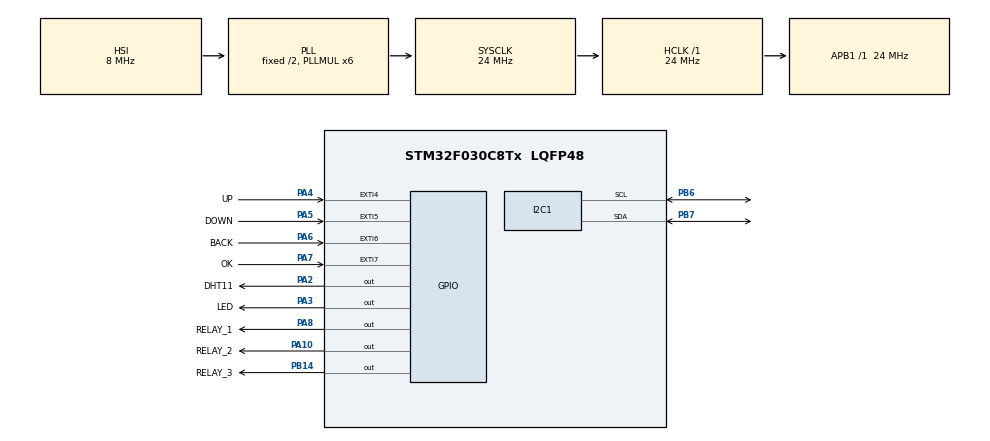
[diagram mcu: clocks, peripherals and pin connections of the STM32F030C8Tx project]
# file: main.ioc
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I2C1.Timing=0x00201D2B
Mcu.Family=STM32F0
Mcu.Name=STM32F030C8Tx
Mcu.Package=LQFP48
NVIC.EXTI4_15_IRQn=true\:0\:0\:false\:false\:true\:true\:true\:true
PA10.GPIO_Label=RELAY_2
PA10.GPIO_Speed=GPIO_SPEED_FREQ_HIGH
PA10.PinState=GPIO_PIN_SET
PA10.Signal=GPIO_Output
PA13.Mode=Serial_Wire
PA13.Signal=SYS_SWDIO
PA14.Mode=Serial_Wire
PA14.Signal=SYS_SWCLK
PA2.GPIO_Label=DHT11
PA2.Signal=GPIO_Output
PA3.GPIO_Label=LED
PA3.Signal=GPIO_Output
PA4.GPIO_Label=UP
PA4.Signal=GPXTI4
PA5.GPIO_Label=DOWN
PA5.Signal=GPXTI5
PA6.GPIO_Label=BACK
PA6.Signal=GPXTI6
PA7.GPIO_Label=OK
PA7.GPIO_ModeDefaultEXTI=GPIO_MODE_IT_RISING
PA7.Signal=GPXTI7
PA8.GPIO_Label=RELAY_1
PA8.GPIO_Speed=GPIO_SPEED_FREQ_HIGH
PA8.PinState=GPIO_PIN_SET
PA8.Signal=GPIO_Output
PB14.GPIO_Label=RELAY_3
PB14.GPIO_Speed=GPIO_SPEED_FREQ_HIGH
PB14.PinState=GPIO_PIN_SET
PB14.Signal=GPIO_Output
PB6.Mode=I2C
PB6.Signal=I2C1_SCL
PB7.Mode=I2C
PB7.Signal=I2C1_SDA
ProjectManager.HeapSize=0x200
ProjectManager.StackSize=0x400
ProjectManager.TargetToolchain=MDK-ARM V5.32
RCC.AHBFreq_Value=24000000
RCC.APB1Freq_Value=24000000
RCC.APB1TimFreq_Value=24000000
RCC.HCLKFreq_Value=24000000
RCC.PLLMUL=RCC_PLL_MUL6
RCC.SYSCLKFreq_VALUE=24000000
RCC.SYSCLKSource=RCC_SYSCLKSOURCE_PLLCLK
TIM3.Period=0xFFFF
TIM3.Prescaler=24-1
VP_TIM3_VS_ClockSourceINT.Mode=Internal
board=custom

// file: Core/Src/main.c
/* USER CODE BEGIN Header */
/**
  ******************************************************************************
  * @file           : main.c
  * @brief          : Main program body
  ******************************************************************************
  * @attention
  *
  * Copyright (c) 2025 STMicroelectronics.
  * All rights reserved.
  *
  * This software is licensed under terms that can be found in the LICENSE file
  * in the root directory of this software component.
  * If no LICENSE file comes with this software, it is provided AS-IS.
  *
  ******************************************************************************
  */
/* USER CODE END Header */
#include "main.h"

/* USER CODE BEGIN Includes */

#include "main.h"
#include "i2c-lcd.h"

#include "stdio.h"
#include "delay_timer.h"

/* USER CODE END Includes */

I2C_HandleTypeDef hi2c1;

TIM_HandleTypeDef htim3;

void SystemClock_Config(void);
static void MX_GPIO_Init(void);
static void MX_I2C1_Init(void);
static void MX_TIM3_Init(void);

/* USER CODE BEGIN 0 */

float a,b;
unsigned short int uiTimeLed = 0,uiTimeReadData = 0;
int TIME_READ_DATA = 100;

uint8_t Rh_byte1, Rh_byte2, Temp_byte1, Temp_byte2;
uint16_t SUM, RH, TEMP;

float Temperature = 0;
float Humidity = 0;
uint8_t Presence = 0;
float setTemp = 30, SET_OK = 30;

void Set_Pin_Output ()
{
	GPIO_InitTypeDef GPIO_InitStruct = {0};
	GPIO_InitStruct.Pin = DHT11_Pin;
	GPIO_InitStruct.Mode = GPIO_MODE_OUTPUT_PP;
	GPIO_InitStruct.Speed = GPIO_SPEED_FREQ_LOW;
	HAL_GPIO_Init(DHT11_GPIO_Port, &GPIO_InitStruct);
}

void Set_Pin_Input ()
{
	GPIO_InitTypeDef GPIO_InitStruct = {0};
	GPIO_InitStruct.Pin = DHT11_Pin;
	GPIO_InitStruct.Mode = GPIO_MODE_INPUT;
	GPIO_InitStruct.Pull = GPIO_PULLUP;
	HAL_GPIO_Init(DHT11_GPIO_Port, &GPIO_InitStruct);
}

void DHT11_Start (void){
		Set_Pin_Output();
		HAL_GPIO_WritePin(DHT11_GPIO_Port , DHT11_Pin ,GPIO_PIN_RESET);
		DELAY_TIM_Ms(&htim3, 20);
		HAL_GPIO_WritePin(DHT11_GPIO_Port , DHT11_Pin ,GPIO_PIN_SET);
		DELAY_TIM_Us(&htim3,40);
	  Set_Pin_Input();
}

uint8_t DHT11_Check_Response (void)
{
	uint8_t Response = 0;
	DELAY_TIM_Us(&htim3,40);
	if (!(HAL_GPIO_ReadPin (DHT11_GPIO_Port , DHT11_Pin)))
	{
		DELAY_TIM_Us(&htim3,80);
		if ((HAL_GPIO_ReadPin (DHT11_GPIO_Port , DHT11_Pin))) Response = 1;
		else Response = -1; // 255
	}
	while ((HAL_GPIO_ReadPin (DHT11_GPIO_Port , DHT11_Pin)));   // wait for the pin to go low

	return Response;
}

uint8_t DHT11_Read (void)
{
	uint8_t i,j;
	for (j=0;j<8;j++)
	{
		while (!(HAL_GPIO_ReadPin (DHT11_GPIO_Port , DHT11_Pin)));   // wait for the pin to go high
		DELAY_TIM_Us(&htim3,40);   // wait for 40 us
		if (!(HAL_GPIO_ReadPin (DHT11_GPIO_Port , DHT11_Pin)))   // if the pin is low
		{
			i&= ~(1<<(7-j));   // write 0
		}
		else i|= (1<<(7-j));  // if the pin is high, write 1
		while ((HAL_GPIO_ReadPin (DHT11_GPIO_Port , DHT11_Pin)));  // wait for the pin to go low
	}
	return i;
}

#define DEBOUNCE_DELAY      50
static uint32_t lastDebounceTime_UP   = 0;
static uint32_t lastDebounceTime_DOWN = 0;
static uint32_t lastDebounceTime_BACK = 0;
static uint32_t lastDebounceTime_OK   = 0;
 static uint8_t relayState = 0 ,relayState_1 = 0 ,relayState_2 = 0, relayState_3 = 0;
void HAL_GPIO_EXTI_Callback(uint16_t GPIO_Pin)
{
    uint32_t currentTick = HAL_GetTick();

    if (GPIO_Pin == UP_Pin)
    {
        if ((currentTick - lastDebounceTime_UP) >= DEBOUNCE_DELAY)
        {
            lastDebounceTime_UP = currentTick;
             relayState = !relayState;
            if (relayState)
            {
               setTemp +=1;
            }
        }
    }
    else if (GPIO_Pin == DOWN_Pin)
    {
        if ((currentTick - lastDebounceTime_DOWN) >= DEBOUNCE_DELAY)
        {
            lastDebounceTime_DOWN = currentTick;
         		relayState_1 = !relayState_1;
            if (relayState_1)
            {
                setTemp-=1;
            }
        }
    }
    else if (GPIO_Pin == BACK_Pin)
    {
        if ((currentTick - lastDebounceTime_BACK) >= DEBOUNCE_DELAY)
        {
            lastDebounceTime_BACK = currentTick;
					 relayState_3 = !relayState_3;
					 if (relayState_3)
            {
                HAL_GPIO_WritePin(GPIOA, RELAY_1_Pin|RELAY_2_Pin, GPIO_PIN_SET);
            }

						else{
							 HAL_GPIO_WritePin(GPIOA, RELAY_1_Pin|RELAY_2_Pin, GPIO_PIN_RESET);
						}
        }
    }
    else if (GPIO_Pin == OK_Pin)
    {
        if ((currentTick - lastDebounceTime_OK) >= DEBOUNCE_DELAY)
        {
            lastDebounceTime_OK = currentTick;
            relayState_2 = !relayState_2;
            if (relayState_2)
            {
                SET_OK = setTemp;
							 HAL_GPIO_WritePin(GPIOA, RELAY_1_Pin|RELAY_2_Pin, GPIO_PIN_SET);
            }
												else{
							 HAL_GPIO_WritePin(GPIOA, RELAY_1_Pin|RELAY_2_Pin, GPIO_PIN_RESET);
						}
        }
    }
}

void SysTick_Handler(void){
  HAL_IncTick();
	if(uiTimeLed != 0){
		uiTimeLed--;
	}
	if(uiTimeReadData != 0){
		uiTimeReadData--;
	}
}

char temp [100], hump[100];
int main(void)
{

  HAL_Init();
  SystemClock_Config();
  MX_GPIO_Init();
  MX_I2C1_Init();
  MX_TIM3_Init();
  /* USER CODE BEGIN 2 */
	DELAY_TIM_Init(&htim3);
	HAL_GPIO_WritePin(GPIOA, DHT11_Pin|LED_Pin, GPIO_PIN_SET);
	HAL_GPIO_WritePin(GPIOA, RELAY_1_Pin|RELAY_2_Pin, GPIO_PIN_RESET);
	lcd_init();
	sprintf(temp, "Nhiet do: %0.1f C", Temperature);
	sprintf(hump, "Do am: %0.1f%%", Humidity);
	lcd_put_cur(0, 0);
  lcd_send_string(temp);
  lcd_put_cur(1, 0);
  lcd_send_string(hump);
  /* USER CODE END 2 */

  /* Infinite loop */
  while (1)
  {
if(uiTimeLed == 0)
		{
			uiTimeLed = 1000;
		}
		else if(uiTimeLed <= 150)
		{
				HAL_GPIO_WritePin(GPIOA, LED_Pin, GPIO_PIN_RESET);
	  }
		else {
			HAL_GPIO_WritePin(GPIOA, LED_Pin, GPIO_PIN_SET);
			}
		if(uiTimeReadData == 0){
				DHT11_Start();
				Presence = DHT11_Check_Response();
				Rh_byte1 = DHT11_Read ();
				Rh_byte2 = DHT11_Read ();
				Temp_byte1 = DHT11_Read ();
				Temp_byte2 = DHT11_Read ();
				SUM = DHT11_Read();
				TEMP = Temp_byte1;
				RH = Rh_byte1;
				Temperature = (float) TEMP;
				Humidity = (float) RH;

			sprintf(temp, "TEMP:%0.1fC||SET:", Temperature);
			sprintf(hump, "HUMP:%0.1f%%||%f", Humidity,setTemp);
			lcd_put_cur(0, 0);
			lcd_send_string(temp);
			lcd_put_cur(1, 0);
			lcd_send_string(hump);
			if(Temperature < SET_OK){
				 HAL_GPIO_WritePin(RELAY_3_GPIO_Port, RELAY_3_Pin, GPIO_PIN_RESET);
			}
			else{
				 HAL_GPIO_WritePin(RELAY_3_GPIO_Port, RELAY_3_Pin, GPIO_PIN_SET);
			}
			uiTimeReadData =TIME_READ_DATA;
			}
  }
}

void SystemClock_Config(void)
{
  RCC_OscInitTypeDef RCC_OscInitStruct = {0};
  RCC_ClkInitTypeDef RCC_ClkInitStruct = {0};
  RCC_PeriphCLKInitTypeDef PeriphClkInit = {0};

  /** Initializes the RCC Oscillators according to the specified parameters
  * in the RCC_OscInitTypeDef structure.
  */
  RCC_OscInitStruct.OscillatorType = RCC_OSCILLATORTYPE_HSI;
  RCC_OscInitStruct.HSIState = RCC_HSI_ON;
  RCC_OscInitStruct.HSICalibrationValue = RCC_HSICALIBRATION_DEFAULT;
  RCC_OscInitStruct.PLL.PLLState = RCC_PLL_ON;
  RCC_OscInitStruct.PLL.PLLSource = RCC_PLLSOURCE_HSI;
  RCC_OscInitStruct.PLL.PLLMUL = RCC_PLL_MUL6;
  RCC_OscInitStruct.PLL.PREDIV = RCC_PREDIV_DIV1;
  if (HAL_RCC_OscConfig(&RCC_OscInitStruct) != HAL_OK)
  {
    Error_Handler();
  }

  /** Initializes the CPU, AHB and APB buses clocks
  */
  RCC_ClkInitStruct.ClockType = RCC_CLOCKTYPE_HCLK|RCC_CLOCKTYPE_SYSCLK
                              |RCC_CLOCKTYPE_PCLK1;
  RCC_ClkInitStruct.SYSCLKSource = RCC_SYSCLKSOURCE_PLLCLK;
  RCC_ClkInitStruct.AHBCLKDivider = RCC_SYSCLK_DIV1;
  RCC_ClkInitStruct.APB1CLKDivider = RCC_HCLK_DIV1;

  if (HAL_RCC_ClockConfig(&RCC_ClkInitStruct, FLASH_LATENCY_0) != HAL_OK)
  {
    Error_Handler();
  }
  PeriphClkInit.PeriphClockSelection = RCC_PERIPHCLK_I2C1;
  PeriphClkInit.I2c1ClockSelection = RCC_I2C1CLKSOURCE_HSI;
  if (HAL_RCCEx_PeriphCLKConfig(&PeriphClkInit) != HAL_OK)
  {
    Error_Handler();
  }
}

static void MX_I2C1_Init(void)
{

  hi2c1.Instance = I2C1;
  hi2c1.Init.Timing = 0x00201D2B;
  hi2c1.Init.OwnAddress1 = 0;
  hi2c1.Init.AddressingMode = I2C_ADDRESSINGMODE_7BIT;
  hi2c1.Init.DualAddressMode = I2C_DUALADDRESS_DISABLE;
  hi2c1.Init.OwnAddress2 = 0;
  hi2c1.Init.OwnAddress2Masks = I2C_OA2_NOMASK;
  hi2c1.Init.GeneralCallMode = I2C_GENERALCALL_DISABLE;
  hi2c1.Init.NoStretchMode = I2C_NOSTRETCH_DISABLE;
  if (HAL_I2C_Init(&hi2c1) != HAL_OK)
  {
    Error_Handler();
  }

  /** Configure Analogue filter
  */
  if (HAL_I2CEx_ConfigAnalogFilter(&hi2c1, I2C_ANALOGFILTER_ENABLE) != HAL_OK)
  {
    Error_Handler();
  }

  /** Configure Digital filter
  */
  if (HAL_I2CEx_ConfigDigitalFilter(&hi2c1, 0) != HAL_OK)
  {
    Error_Handler();
  }

}

static void MX_TIM3_Init(void)
{

  TIM_ClockConfigTypeDef sClockSourceConfig = {0};
  TIM_MasterConfigTypeDef sMasterConfig = {0};

  htim3.Instance = TIM3;
  htim3.Init.Prescaler = 24-1;
  htim3.Init.CounterMode = TIM_COUNTERMODE_UP;
  htim3.Init.Period = 0xFFFF;
  htim3.Init.ClockDivision = TIM_CLOCKDIVISION_DIV1;
  htim3.Init.AutoReloadPreload = TIM_AUTORELOAD_PRELOAD_DISABLE;
  if (HAL_TIM_Base_Init(&htim3) != HAL_OK)
  {
    Error_Handler();
  }
  sClockSourceConfig.ClockSource = TIM_CLOCKSOURCE_INTERNAL;
  if (HAL_TIM_ConfigClockSource(&htim3, &sClockSourceConfig) != HAL_OK)
  {
    Error_Handler();
  }
  sMasterConfig.MasterOutputTrigger = TIM_TRGO_RESET;
  sMasterConfig.MasterSlaveMode = TIM_MASTERSLAVEMODE_DISABLE;
  if (HAL_TIMEx_MasterConfigSynchronization(&htim3, &sMasterConfig) != HAL_OK)
  {
    Error_Handler();
  }

}

static void MX_GPIO_Init(void)
{
  GPIO_InitTypeDef GPIO_InitStruct = {0};

  /* GPIO Ports Clock Enable */
  __HAL_RCC_GPIOA_CLK_ENABLE();
  __HAL_RCC_GPIOB_CLK_ENABLE();

  /*Configure GPIO pin Output Level */
  HAL_GPIO_WritePin(GPIOA, DHT11_Pin|LED_Pin, GPIO_PIN_RESET);

  /*Configure GPIO pin Output Level */
  HAL_GPIO_WritePin(RELAY_3_GPIO_Port, RELAY_3_Pin, GPIO_PIN_SET);

  /*Configure GPIO pin Output Level */
  HAL_GPIO_WritePin(GPIOA, RELAY_1_Pin|RELAY_2_Pin, GPIO_PIN_SET);

  /*Configure GPIO pins : DHT11_Pin LED_Pin */
  GPIO_InitStruct.Pin = DHT11_Pin|LED_Pin;
  GPIO_InitStruct.Mode = GPIO_MODE_OUTPUT_PP;
  GPIO_InitStruct.Pull = GPIO_NOPULL;
  GPIO_InitStruct.Speed = GPIO_SPEED_FREQ_LOW;
  HAL_GPIO_Init(GPIOA, &GPIO_InitStruct);

  /*Configure GPIO pins : UP_Pin DOWN_Pin BACK_Pin OK_Pin */
  GPIO_InitStruct.Pin = UP_Pin|DOWN_Pin|BACK_Pin|OK_Pin;
  GPIO_InitStruct.Mode = GPIO_MODE_IT_RISING;
  GPIO_InitStruct.Pull = GPIO_NOPULL;
  HAL_GPIO_Init(GPIOA, &GPIO_InitStruct);

  /*Configure GPIO pin : RELAY_3_Pin */
  GPIO_InitStruct.Pin = RELAY_3_Pin;
  GPIO_InitStruct.Mode = GPIO_MODE_OUTPUT_PP;
  GPIO_InitStruct.Pull = GPIO_NOPULL;
  GPIO_InitStruct.Speed = GPIO_SPEED_FREQ_HIGH;
  HAL_GPIO_Init(RELAY_3_GPIO_Port, &GPIO_InitStruct);

  /*Configure GPIO pins : RELAY_1_Pin RELAY_2_Pin */
  GPIO_InitStruct.Pin = RELAY_1_Pin|RELAY_2_Pin;
  GPIO_InitStruct.Mode = GPIO_MODE_OUTPUT_PP;
  GPIO_InitStruct.Pull = GPIO_NOPULL;
  GPIO_InitStruct.Speed = GPIO_SPEED_FREQ_HIGH;
  HAL_GPIO_Init(GPIOA, &GPIO_InitStruct);

  /* EXTI interrupt init*/
  HAL_NVIC_SetPriority(EXTI4_15_IRQn, 0, 0);
  HAL_NVIC_EnableIRQ(EXTI4_15_IRQn);

}

void Error_Handler(void)
{
  __disable_irq();
  while (1)
  {
  }
}
